# AT91SAM9G10 register map
Vendor: Atmel; File version: 20130207
CPU: 
Registers are 32-bit, read-write, no defined reset value unless marked. A register's access mark holds for its fields unless they carry their own. Offsets are from the block's base; [hi:lo] are bit positions; {n}, {i} and the like mark numbered series.

## MCI — MultiMedia Card Interface
Base 0xFFFA8000; register names take the prefix MCI_
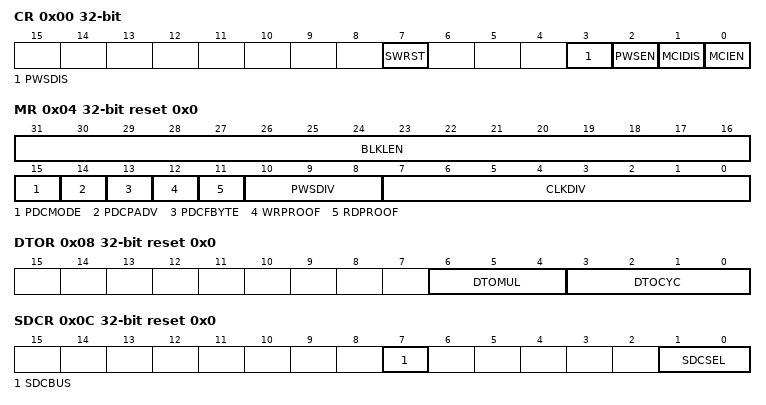
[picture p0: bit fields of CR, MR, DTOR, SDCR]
0x00 CR wo — Control Register
  [7] SWRST — Software Reset
  [3] PWSDIS — Power Save Mode Disable
  [2] PWSEN — Power Save Mode Enable
  [1] MCIDIS — Multi-Media Interface Disable
  [0] MCIEN — Multi-Media Interface Enable
0x04 MR reset 0x0 — Mode Register
  [31:16] BLKLEN — Data Block Length
  [15] PDCMODE — PDC-oriented Mode
  [14] PDCPADV — PDC Padding Value
  [13] PDCFBYTE — PDC Force Byte Transfer
  [12] WRPROOF
  [11] RDPROOF
  [10:8] PWSDIV — Power Saving Divider
  [7:0] CLKDIV — Clock Divider
0x08 DTOR reset 0x0 — Data Timeout Register
  [6:4] DTOMUL — Data Timeout Multiplier
  [3:0] DTOCYC — Data Timeout Cycle Number
0x0C SDCR reset 0x0 — SD/SDIO Card Register
  [7] SDCBUS — SDCard/SDIO Bus Width
  [1:0] SDCSEL — SDCard/SDIO Slot
0x10 ARGR reset 0x0 — Argument Register
  [31:0] ARG — Command Argument
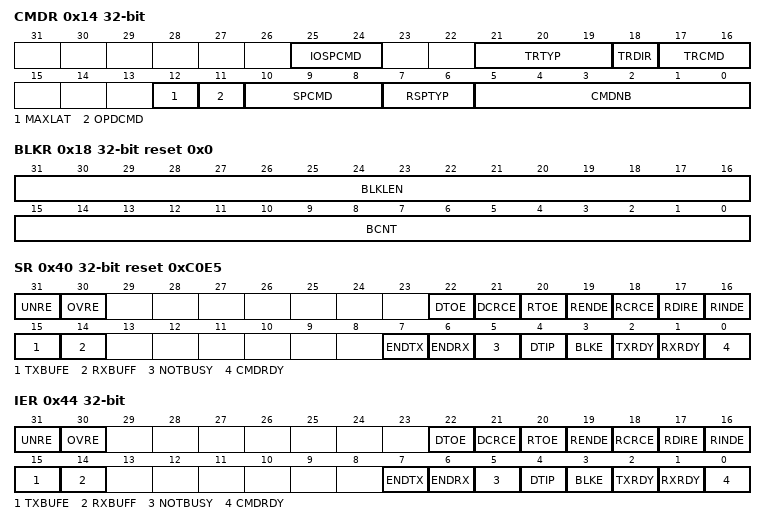
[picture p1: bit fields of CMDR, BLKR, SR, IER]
0x14 CMDR wo — Command Register
  [25:24] IOSPCMD — SDIO Special Command
  [21:19] TRTYP — Transfer Type
  [18] TRDIR — Transfer Direction
  [17:16] TRCMD — Transfer Command
  [12] MAXLAT — Max Latency for Command to Response
  [11] OPDCMD — Open Drain Command
  [10:8] SPCMD — Special Command
  [7:6] RSPTYP — Response Type
  [5:0] CMDNB — Command Number
0x18 BLKR reset 0x0 — Block Register
  [31:16] BLKLEN — Data Block Length
  [15:0] BCNT — MMC/SDIO Block Count - SDIO Byte Count
{0x20+4i} RSPR[{i}] ro (i=0..3) — Response Register
  [31:0] RSP — Response
0x30 RDR ro reset 0x0 — Receive Data Register
  [31:0] DATA — Data to Read
0x34 TDR wo — Transmit Data Register
  [31:0] DATA — Data to Write
0x40 SR ro reset 0xC0E5 — Status Register
  [31] UNRE — Underrun
  [30] OVRE — Overrun
  [22] DTOE — Data Time-out Error
  [21] DCRCE — Data CRC Error
  [20] RTOE — Response Time-out Error
  [19] RENDE — Response End Bit Error
  [18] RCRCE — Response CRC Error
  [17] RDIRE — Response Direction Error
  [16] RINDE — Response Index Error
  [15] TXBUFE — TX Buffer Empty
  [14] RXBUFF — RX Buffer Full
  [7] ENDTX — End of TX Buffer
  [6] ENDRX — End of RX Buffer
  [5] NOTBUSY — MCI Not Busy
  [4] DTIP — Data Transfer in Progress
  [3] BLKE — Data Block Ended
  [2] TXRDY — Transmit Ready
  [1] RXRDY — Receiver Ready
  [0] CMDRDY — Command Ready
0x44 IER wo — Interrupt Enable Register
  [31] UNRE — UnderRun Interrupt Enable
  [30] OVRE — Overrun Interrupt Enable
  [22] DTOE — Data Time-out Error Interrupt Enable
  [21] DCRCE — Data CRC Error Interrupt Enable
  [20] RTOE — Response Time-out Error Interrupt Enable
  [19] RENDE — Response End Bit Error Interrupt Enable
  [18] RCRCE — Response CRC Error Interrupt Enable
  [17] RDIRE — Response Direction Error Interrupt Enable
  [16] RINDE — Response Index Error Interrupt Enable
  [15] TXBUFE — Transmit Buffer Empty Interrupt Enable
  [14] RXBUFF — Receive Buffer Full Interrupt Enable
  [7] ENDTX — End of Transmit Buffer Interrupt Enable
  [6] ENDRX — End of Receive Buffer Interrupt Enable
  [5] NOTBUSY — Data Not Busy Interrupt Enable
  [4] DTIP — Data Transfer in Progress Interrupt Enable
  [3] BLKE — Data Block Ended Interrupt Enable
  [2] TXRDY — Transmit Ready Interrupt Enable
  [1] RXRDY — Receiver Ready Interrupt Enable
  [0] CMDRDY — Command Ready Interrupt Enable
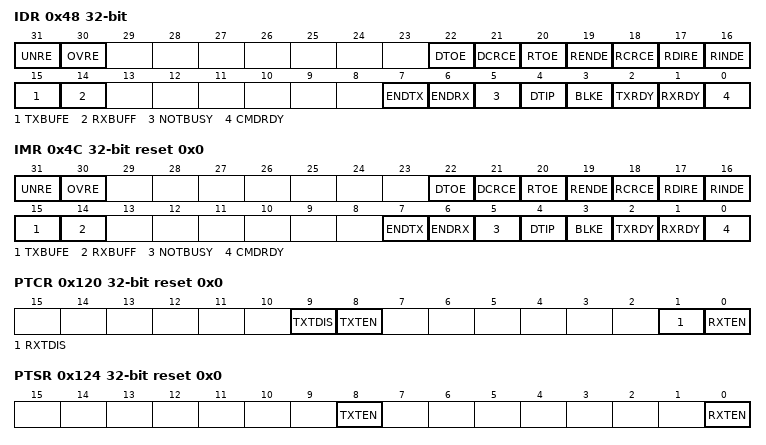
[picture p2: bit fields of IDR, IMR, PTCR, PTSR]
0x48 IDR wo — Interrupt Disable Register
  [31] UNRE — UnderRun Interrupt Disable
  [30] OVRE — Overrun Interrupt Disable
  [22] DTOE — Data Time-out Error Interrupt Disable
  [21] DCRCE — Data CRC Error Interrupt Disable
  [20] RTOE — Response Time-out Error Interrupt Disable
  [19] RENDE — Response End Bit Error Interrupt Disable
  [18] RCRCE — Response CRC Error Interrupt Disable
  [17] RDIRE — Response Direction Error Interrupt Disable
  [16] RINDE — Response Index Error Interrupt Disable
  [15] TXBUFE — Transmit Buffer Empty Interrupt Disable
  [14] RXBUFF — Receive Buffer Full Interrupt Disable
  [7] ENDTX — End of Transmit Buffer Interrupt Disable
  [6] ENDRX — End of Receive Buffer Interrupt Disable
  [5] NOTBUSY — Data Not Busy Interrupt Disable
  [4] DTIP — Data Transfer in Progress Interrupt Disable
  [3] BLKE — Data Block Ended Interrupt Disable
  [2] TXRDY — Transmit Ready Interrupt Disable
  [1] RXRDY — Receiver Ready Interrupt Disable
  [0] CMDRDY — Command Ready Interrupt Disable
0x4C IMR ro reset 0x0 — Interrupt Mask Register
  [31] UNRE — UnderRun Interrupt Mask
  [30] OVRE — Overrun Interrupt Mask
  [22] DTOE — Data Time-out Error Interrupt Mask
  [21] DCRCE — Data CRC Error Interrupt Mask
  [20] RTOE — Response Time-out Error Interrupt Mask
  [19] RENDE — Response End Bit Error Interrupt Mask
  [18] RCRCE — Response CRC Error Interrupt Mask
  [17] RDIRE — Response Direction Error Interrupt Mask
  [16] RINDE — Response Index Error Interrupt Mask
  [15] TXBUFE — Transmit Buffer Empty Interrupt Mask
  [14] RXBUFF — Receive Buffer Full Interrupt Mask
  [7] ENDTX — End of Transmit Buffer Interrupt Mask
  [6] ENDRX — End of Receive Buffer Interrupt Mask
  [5] NOTBUSY — Data Not Busy Interrupt Mask
  [4] DTIP — Data Transfer in Progress Interrupt Mask
  [3] BLKE — Data Block Ended Interrupt Mask
  [2] TXRDY — Transmit Ready Interrupt Mask
  [1] RXRDY — Receiver Ready Interrupt Mask
  [0] CMDRDY — Command Ready Interrupt Mask
0x100 RPR reset 0x0 — Receive Pointer Register
  [31:0] RXPTR
0x104 RCR reset 0x0 — Receive Counter Register
  [15:0] RXCTR
0x108 TPR reset 0x0 — Transmit Pointer Register
  [31:0] TXPTR — Transmit Counter Register
0x10C TCR reset 0x0 — Transmit Counter Register
  [15:0] TXCTR
0x110 RNPR reset 0x0 — Receive Next Pointer Register
  [31:0] RXNPTR — Receive Next Pointer
0x114 RNCR reset 0x0 — Receive Next Counter Register
  [15:0] RXNCTR — Receive Next Counter
0x118 TNPR reset 0x0 — Transmit Next Pointer Register
  [31:0] TXNPTR — Transmit Next Pointer
0x11C TNCR reset 0x0 — Transmit Next Counter Register
  [15:0] TXNCTR — Transmit Counter Next
0x120 PTCR wo reset 0x0 — Transfer Control Register
  [9] TXTDIS — Transmitter Transfer Disable
  [8] TXTEN — Transmitter Transfer Enable
  [1] RXTDIS — Receiver Transfer Disable
  [0] RXTEN — Receiver Transfer Enable
0x124 PTSR ro reset 0x0 — Transfer Status Register
  [8] TXTEN — Transmitter Transfer Enable
  [0] RXTEN — Receiver Transfer Enable
